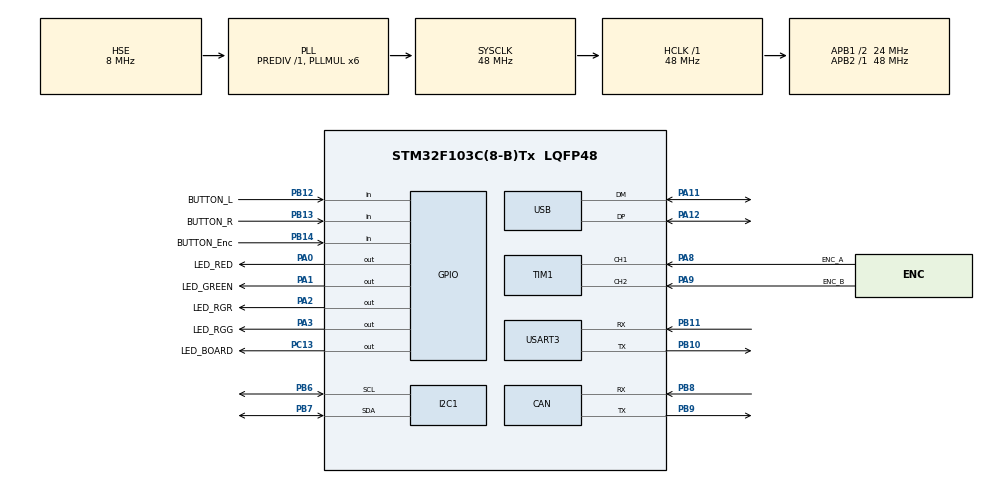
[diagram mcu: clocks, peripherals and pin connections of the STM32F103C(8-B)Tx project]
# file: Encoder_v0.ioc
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CAN.CalculateTimeBit=2000
CAN.CalculateTimeQuantum=666.6666666666666
I2C1.I2C_Mode=I2C_Standard
Mcu.Family=STM32F1
Mcu.Name=STM32F103C(8-B)Tx
Mcu.Package=LQFP48
NVIC.PriorityGroup=NVIC_PRIORITYGROUP_4
NVIC.USB_LP_CAN1_RX0_IRQn=true\:0\:0\:false\:false\:true\:false\:true
PA0-WKUP.GPIO_Label=LED_RED
PA0-WKUP.Signal=GPIO_Output
PA1.GPIO_Label=LED_GREEN
PA1.Signal=GPIO_Output
PA11.Mode=Device
PA11.Signal=USB_DM
PA12.Mode=Device
PA12.Signal=USB_DP
PA13.Mode=Serial_Wire
PA13.Signal=SYS_JTMS-SWDIO
PA14.Mode=Serial_Wire
PA14.Signal=SYS_JTCK-SWCLK
PA2.GPIO_Label=LED_RGR
PA2.Signal=GPIO_Output
PA3.GPIO_Label=LED_RGG
PA3.Signal=GPIO_Output
PA8.GPIO_Label=ENC_A
PA8.Signal=S_TIM1_CH1
PA9.GPIO_Label=ENC_B
PA9.Signal=S_TIM1_CH2
PB10.Mode=Asynchronous
PB10.Signal=USART3_TX
PB11.Mode=Asynchronous
PB11.Signal=USART3_RX
PB12.GPIO_Label=BUTTON_L
PB12.GPIO_PuPd=GPIO_PULLUP
PB12.Signal=GPIO_Input
PB13.GPIO_Label=BUTTON_R
PB13.GPIO_PuPd=GPIO_PULLUP
PB13.Signal=GPIO_Input
PB14.GPIO_Label=BUTTON_Enc
PB14.GPIO_PuPd=GPIO_PULLUP
PB14.Signal=GPIO_Input
PB6.Mode=I2C
PB6.Signal=I2C1_SCL
PB7.Mode=I2C
PB7.Signal=I2C1_SDA
PB8.Mode=Master
PB8.Signal=CAN_RX
PB9.Mode=Master
PB9.Signal=CAN_TX
PC13-TAMPER-RTC.GPIO_Label=LED_BOARD
PC13-TAMPER-RTC.Signal=GPIO_Output
PC14-OSC32_IN.Mode=LSE-External-Oscillator
PC14-OSC32_IN.Signal=RCC_OSC32_IN
PC15-OSC32_OUT.Mode=LSE-External-Oscillator
PC15-OSC32_OUT.Signal=RCC_OSC32_OUT
PD0-OSC_IN.Mode=HSE-External-Oscillator
PD0-OSC_IN.Signal=RCC_OSC_IN
PD1-OSC_OUT.Mode=HSE-External-Oscillator
PD1-OSC_OUT.Signal=RCC_OSC_OUT
ProjectManager.HeapSize=0x200
ProjectManager.StackSize=0x400
ProjectManager.TargetToolchain=Other Toolchains (GPDSC)
RCC.AHBFreq_Value=48000000
RCC.APB1CLKDivider=RCC_HCLK_DIV2
RCC.APB1Freq_Value=24000000
RCC.APB1TimFreq_Value=48000000
RCC.APB2Freq_Value=48000000
RCC.APB2TimFreq_Value=48000000
RCC.HCLKFreq_Value=48000000
RCC.PLLMUL=RCC_PLL_MUL6
RCC.SYSCLKFreq_VALUE=48000000
RCC.SYSCLKSource=RCC_SYSCLKSOURCE_PLLCLK
RCC.USBFreq_Value=48000000
SH.S_TIM1_CH1.0=TIM1_CH1,Encoder_Interface
SH.S_TIM1_CH2.0=TIM1_CH2,Encoder_Interface
TIM1.EncoderMode=TIM_ENCODERMODE_TI12
USART3.VirtualMode=VM_ASYNC
USB_DEVICE.CLASS_NAME_FS=CDC
USB_DEVICE.VirtualMode=Cdc
USB_DEVICE.VirtualModeFS=Cdc_FS
VP_TIM2_VS_ClockSourceINT.Mode=Internal
VP_USB_DEVICE_VS_USB_DEVICE_CDC_FS.Mode=CDC_FS
board=custom

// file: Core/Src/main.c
/* USER CODE BEGIN Header */
/**
  ******************************************************************************
  * @file           : main.c
  * @brief          : Main program body
  ******************************************************************************
  * @attention
  *
  * <h2><center>&copy; Copyright (c) 2020 STMicroelectronics.
  * All rights reserved.</center></h2>
  *
  * This software component is licensed by ST under Ultimate Liberty license
  * SLA0044, the "License"; You may not use this file except in compliance with
  * the License. You may obtain a copy of the License at:
  *                             www.st.com/SLA0044
  *
  ******************************************************************************
  */
/* USER CODE END Header */

#include "main.h"
#include "can.h"
#include "i2c.h"
#include "tim.h"
#include "usart.h"
#include "usb_device.h"
#include "gpio.h"

/* USER CODE BEGIN Includes */
#include <SysprogsProfiler.h>
#include "stdbool.h"

/* USER CODE END Includes */

void SystemClock_Config(void);

int main(void)
{
  /* USER CODE BEGIN 1 *///-------------------------------------------------------- -//-------------------------------------------------------- -//--------------------------------------------------------

  /* USER CODE END 1 *///-------------------------------------------------------- -//-------------------------------------------------------- -//-------------------------------------------------------- -

  /* MCU Configuration--------------------------------------------------------*/

  /* Reset of all peripherals, Initializes the Flash interface and the Systick. */
  HAL_Init();

  /* USER CODE BEGIN Init */
  InitializeInstrumentingProfiler();

  /* USER CODE END Init */

  /* Configure the system clock */
  SystemClock_Config();

  /* Initialize all configured peripherals */
  MX_GPIO_Init();
  MX_CAN_Init();
  MX_I2C1_Init();
  MX_TIM1_Init();
  MX_TIM2_Init();
  MX_USART3_UART_Init();
  MX_USB_DEVICE_Init();
  /* USER CODE BEGIN 2 *///-------------------------------------------------------- -//-------------------------------------------------------- -//-------------------------------------------------------- -

  /* USER CODE END 2 *///-------------------------------------------------------- -//-------------------------------------------------------- -//-------------------------------------------------------- -

  /* Infinite loop */
  /* USER CODE BEGIN WHILE *///-------------------------------------------------------- -//-------------------------------------------------------- -//-------------------------------------------------------- -
  while (true)
  {
    /* USER CODE END WHILE *///-------------------------------------------------------- -//-------------------------------------------------------- -//-------------------------------------------------------- -
      if (HAL_GPIO_ReadPin(BUTTON_Enc_GPIO_Port, BUTTON_Enc_Pin) == GPIO_PIN_SET)
      {
          HAL_GPIO_WritePin(LED_RGG_GPIO_Port, LED_RGG_Pin, GPIO_PIN_SET);
          HAL_GPIO_WritePin(LED_RGR_GPIO_Port, LED_RGR_Pin, GPIO_PIN_RESET);
      }
      else
      {
          HAL_GPIO_WritePin(LED_RGR_GPIO_Port, LED_RGR_Pin, GPIO_PIN_SET);
          HAL_GPIO_WritePin(LED_RGG_GPIO_Port, LED_RGG_Pin, GPIO_PIN_RESET);
      }
    /* USER CODE BEGIN 3 *///-------------------------------------------------------- -//-------------------------------------------------------- -//-------------------------------------------------------- -
  }
  /* USER CODE END 3 *///-------------------------------------------------------- -//-------------------------------------------------------- -//-------------------------------------------------------- -
}

void SystemClock_Config(void)
{
  RCC_OscInitTypeDef RCC_OscInitStruct = {0};
  RCC_ClkInitTypeDef RCC_ClkInitStruct = {0};
  RCC_PeriphCLKInitTypeDef PeriphClkInit = {0};

  /** Initializes the CPU, AHB and APB busses clocks
  */
  RCC_OscInitStruct.OscillatorType = RCC_OSCILLATORTYPE_HSE;
  RCC_OscInitStruct.HSEState = RCC_HSE_ON;
  RCC_OscInitStruct.HSEPredivValue = RCC_HSE_PREDIV_DIV1;
  RCC_OscInitStruct.HSIState = RCC_HSI_ON;
  RCC_OscInitStruct.PLL.PLLState = RCC_PLL_ON;
  RCC_OscInitStruct.PLL.PLLSource = RCC_PLLSOURCE_HSE;
  RCC_OscInitStruct.PLL.PLLMUL = RCC_PLL_MUL6;
  if (HAL_RCC_OscConfig(&RCC_OscInitStruct) != HAL_OK)
  {
    Error_Handler();
  }
  /** Initializes the CPU, AHB and APB busses clocks
  */
  RCC_ClkInitStruct.ClockType = RCC_CLOCKTYPE_HCLK|RCC_CLOCKTYPE_SYSCLK
                              |RCC_CLOCKTYPE_PCLK1|RCC_CLOCKTYPE_PCLK2;
  RCC_ClkInitStruct.SYSCLKSource = RCC_SYSCLKSOURCE_PLLCLK;
  RCC_ClkInitStruct.AHBCLKDivider = RCC_SYSCLK_DIV1;
  RCC_ClkInitStruct.APB1CLKDivider = RCC_HCLK_DIV2;
  RCC_ClkInitStruct.APB2CLKDivider = RCC_HCLK_DIV1;

  if (HAL_RCC_ClockConfig(&RCC_ClkInitStruct, FLASH_LATENCY_1) != HAL_OK)
  {
    Error_Handler();
  }
  PeriphClkInit.PeriphClockSelection = RCC_PERIPHCLK_USB;
  PeriphClkInit.UsbClockSelection = RCC_USBCLKSOURCE_PLL;
  if (HAL_RCCEx_PeriphCLKConfig(&PeriphClkInit) != HAL_OK)
  {
    Error_Handler();
  }
}

/* USER CODE BEGIN 4 *///-------------------------------------------------------- -//-------------------------------------------------------- -//--------------------------------------------------------

/* USER CODE END 4 *///-------------------------------------------------------- -//-------------------------------------------------------- -//-------------------------------------------------------- -

void Error_Handler(void)
{
}

/************************ (C) COPYRIGHT STMicroelectronics *****END OF FILE****/
